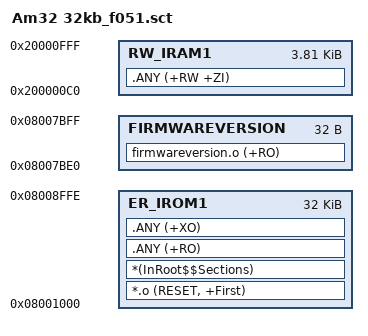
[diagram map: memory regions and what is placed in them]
; *************************************************************
; *** Scatter-Loading Description File generated by uVision ***
; *************************************************************

LR_IROM1 0x08001000 0x00007FFF  {    ; load region size_region
  ER_IROM1 0x08001000 0x00007FFF  {  ; load address = execution address
   *.o (RESET, +First)
   *(InRoot$$Sections)
   .ANY (+RO)
   .ANY (+XO)
  }
  RW_IRAM1 0x200000C0 0x00000F40  {  ; RW data
   .ANY (+RW +ZI)
  }
}
LR_FIRMWAREVERSION 0x08007BE0 0x00000020{
	FIRMWAREVERSION 0x08007BE0 0x00000020{
	firmwareversion.o (+RO)
	}
}
